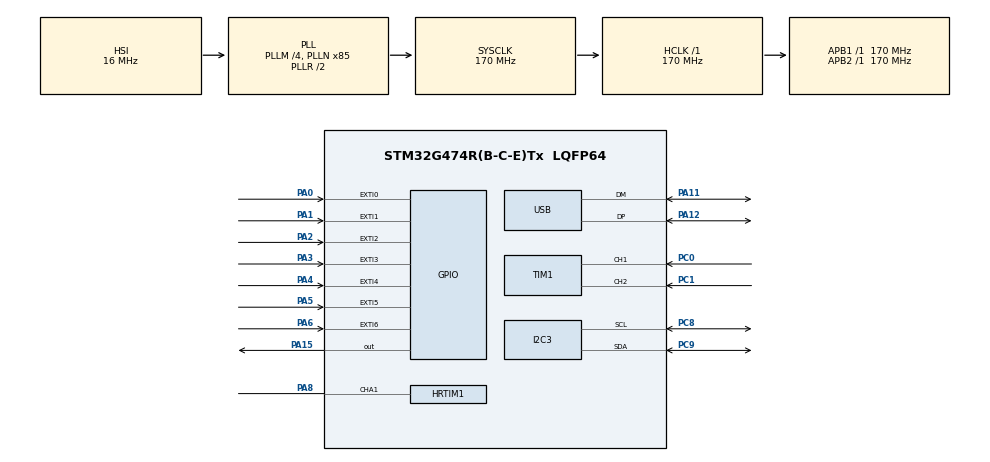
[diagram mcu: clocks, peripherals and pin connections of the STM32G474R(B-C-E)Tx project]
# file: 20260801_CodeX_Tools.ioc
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I2C3.Timing=0x40621236
Mcu.Family=STM32G4
Mcu.Name=STM32G474R(B-C-E)Tx
Mcu.Package=LQFP64
NVIC.PriorityGroup=NVIC_PRIORITYGROUP_4
NVIC.USB_LP_IRQn=true\:0\:0\:false\:false\:true\:false\:true\:true
PA0.GPIO_ModeDefaultEXTI=GPIO_MODE_EVT_FALLING
PA0.GPIO_PuPd=GPIO_PULLUP
PA0.Signal=GPXTI0
PA1.GPIO_ModeDefaultEXTI=GPIO_MODE_EVT_FALLING
PA1.GPIO_PuPd=GPIO_PULLUP
PA1.Signal=GPXTI1
PA11.Mode=Device
PA11.Signal=USB_DM
PA12.Mode=Device
PA12.Signal=USB_DP
PA13.Mode=Serial_Wire
PA13.Signal=SYS_JTMS-SWDIO
PA14.Mode=Serial_Wire
PA14.Signal=SYS_JTCK-SWCLK
PA15.GPIO_PuPd=GPIO_NOPULL
PA15.Signal=GPIO_Output
PA2.GPIO_ModeDefaultEXTI=GPIO_MODE_EVT_FALLING
PA2.GPIO_PuPd=GPIO_PULLUP
PA2.Signal=GPXTI2
PA3.GPIO_ModeDefaultEXTI=GPIO_MODE_EVT_FALLING
PA3.GPIO_PuPd=GPIO_PULLUP
PA3.Signal=GPXTI3
PA4.GPIO_ModeDefaultEXTI=GPIO_MODE_EVT_FALLING
PA4.GPIO_PuPd=GPIO_PULLUP
PA4.Signal=GPXTI4
PA5.GPIO_ModeDefaultEXTI=GPIO_MODE_EVT_FALLING
PA5.GPIO_PuPd=GPIO_PULLUP
PA5.Signal=GPXTI5
PA6.GPIO_ModeDefaultEXTI=GPIO_MODE_EVT_FALLING
PA6.GPIO_PuPd=GPIO_PULLUP
PA6.Signal=GPXTI6
PA8.Mode=Output_TA1
PA8.Signal=HRTIM1_CHA1
PC0.Signal=S_TIM1_CH1
PC1.Signal=S_TIM1_CH2
PC8.Mode=I2C
PC8.Signal=I2C3_SCL
PC9.Mode=I2C
PC9.Signal=I2C3_SDA
ProjectManager.HeapSize=0x200
ProjectManager.StackSize=0x400
ProjectManager.TargetToolchain=STM32CubeIDE
RCC.ADC12Freq_Value=170000000
RCC.ADC345Freq_Value=170000000
RCC.AHBFreq_Value=170000000
RCC.APB1Freq_Value=170000000
RCC.APB1TimFreq_Value=170000000
RCC.APB2Freq_Value=170000000
RCC.APB2TimFreq_Value=170000000
RCC.CK48CLockSelection=RCC_USBCLKSOURCE_HSI48
RCC.CortexFreq_Value=170000000
RCC.EXTERNAL_CLOCK_VALUE=12288000
RCC.HCLKFreq_Value=170000000
RCC.HSE_VALUE=8000000
RCC.HSI48_VALUE=48000000
RCC.HSI_VALUE=16000000
RCC.LSE_VALUE=32768
RCC.PLLM=RCC_PLLM_DIV4
RCC.PLLN=85
RCC.PWR_Regulator_Voltage_Scale=PWR_REGULATOR_VOLTAGE_SCALE1_BOOST
RCC.SYSCLKFreq_VALUE=170000000
RCC.SYSCLKSource=RCC_SYSCLKSOURCE_PLLCLK
RCC.USBFreq_Value=48000000
RCC.VCOOutputFreq_Value=340000000
SH.S_TIM1_CH1.0=TIM1_CH1,Encoder_Interface
SH.S_TIM1_CH2.0=TIM1_CH2,Encoder_Interface
USB_DEVICE.CLASS_NAME_FS=CDC
USB_DEVICE.VirtualMode=Cdc
USB_DEVICE.VirtualModeFS=Cdc_FS
VP_SYS_VS_DBSignals.Mode=DisableDeadBatterySignals
VP_USB_DEVICE_VS_USB_DEVICE_CDC_FS.Mode=CDC_FS
board=custom

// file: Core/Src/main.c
/* USER CODE BEGIN Header */
/**
  ******************************************************************************
  * @file           : main.c
  * @brief          : Main program body
  ******************************************************************************
  * @attention
  *
  * Copyright (c) 2026 STMicroelectronics.
  * All rights reserved.
  *
  * This software is licensed under terms that can be found in the LICENSE file
  * in the root directory of this software component.
  * If no LICENSE file comes with this software, it is provided AS-IS.
  *
  ******************************************************************************
  */
/* USER CODE END Header */
#include "main.h"
#include "hrtim.h"
#include "i2c.h"
#include "tim.h"
#include "usb_device.h"
#include "gpio.h"

/* USER CODE BEGIN Includes */
#include "my_def.h"
#include "app.h"
#include "app_cfg.h"
/* USER CODE END Includes */

void SystemClock_Config(void);

int main(void)
{

  /* MCU Configuration--------------------------------------------------------*/

  /* Reset of all peripherals, Initializes the Flash interface and the Systick. */
  HAL_Init();

  /* Configure the system clock */
  SystemClock_Config();

  /* Initialize all configured peripherals */
  MX_GPIO_Init();
  MX_HRTIM1_Init();
  MX_I2C3_Init();
  MX_TIM1_Init();
  MX_USB_Device_Init();
  /* USER CODE BEGIN 2 */

  app_init();

  /* USER CODE END 2 */

  /* Infinite loop */
  while (1)
  {

    /* USER CODE BEGIN 3 */

    app_tick();
    HAL_Delay(APP_TICK_MS);

  }
  /* USER CODE END 3 */
}

void SystemClock_Config(void)
{
  RCC_OscInitTypeDef RCC_OscInitStruct = {0};
  RCC_ClkInitTypeDef RCC_ClkInitStruct = {0};

  /** Configure the main internal regulator output voltage
  */
  HAL_PWREx_ControlVoltageScaling(PWR_REGULATOR_VOLTAGE_SCALE1_BOOST);

  /** Initializes the RCC Oscillators according to the specified parameters
  * in the RCC_OscInitTypeDef structure.
  */
  RCC_OscInitStruct.OscillatorType = RCC_OSCILLATORTYPE_HSI|RCC_OSCILLATORTYPE_HSI48;
  RCC_OscInitStruct.HSIState = RCC_HSI_ON;
  RCC_OscInitStruct.HSICalibrationValue = RCC_HSICALIBRATION_DEFAULT;
  RCC_OscInitStruct.HSI48State = RCC_HSI48_ON;
  RCC_OscInitStruct.PLL.PLLState = RCC_PLL_ON;
  RCC_OscInitStruct.PLL.PLLSource = RCC_PLLSOURCE_HSI;
  RCC_OscInitStruct.PLL.PLLM = RCC_PLLM_DIV4;
  RCC_OscInitStruct.PLL.PLLN = 85;
  RCC_OscInitStruct.PLL.PLLP = RCC_PLLP_DIV2;
  RCC_OscInitStruct.PLL.PLLQ = RCC_PLLQ_DIV2;
  RCC_OscInitStruct.PLL.PLLR = RCC_PLLR_DIV2;
  if (HAL_RCC_OscConfig(&RCC_OscInitStruct) != HAL_OK)
  {
    Error_Handler();
  }

  /** Initializes the CPU, AHB and APB buses clocks
  */
  RCC_ClkInitStruct.ClockType = RCC_CLOCKTYPE_HCLK|RCC_CLOCKTYPE_SYSCLK
                              |RCC_CLOCKTYPE_PCLK1|RCC_CLOCKTYPE_PCLK2;
  RCC_ClkInitStruct.SYSCLKSource = RCC_SYSCLKSOURCE_PLLCLK;
  RCC_ClkInitStruct.AHBCLKDivider = RCC_SYSCLK_DIV1;
  RCC_ClkInitStruct.APB1CLKDivider = RCC_HCLK_DIV1;
  RCC_ClkInitStruct.APB2CLKDivider = RCC_HCLK_DIV1;

  if (HAL_RCC_ClockConfig(&RCC_ClkInitStruct, FLASH_LATENCY_4) != HAL_OK)
  {
    Error_Handler();
  }
}

void Error_Handler(void)
{
  __disable_irq();
  while (1)
  {
  }
}
